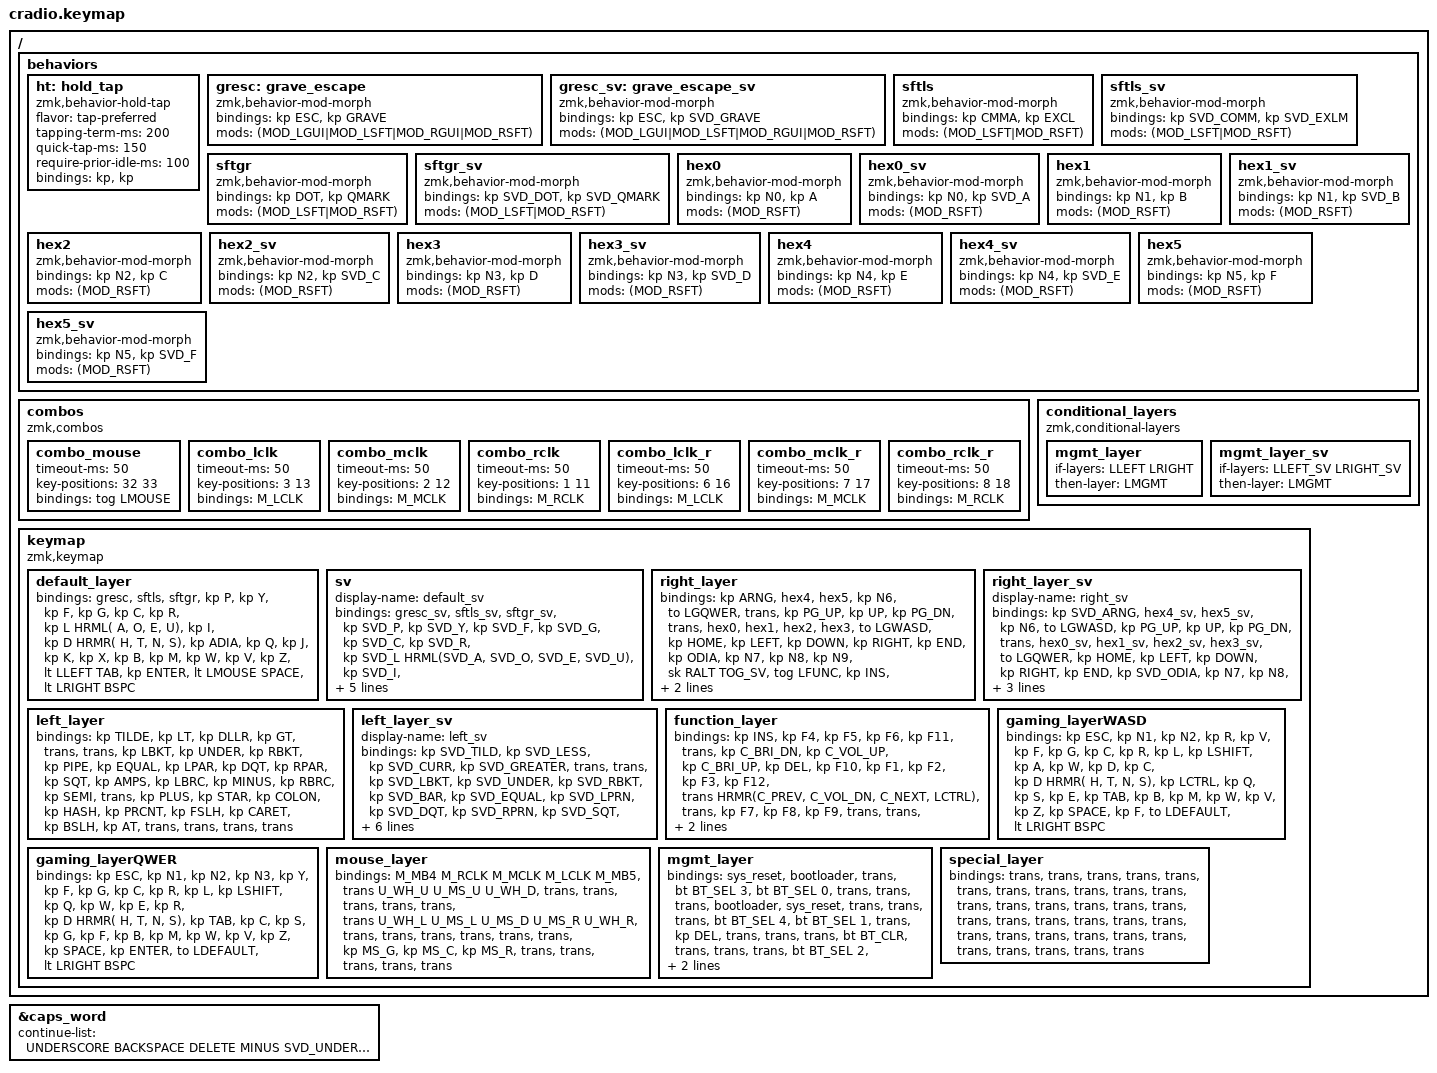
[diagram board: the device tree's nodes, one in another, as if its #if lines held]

// Copyright (c) 2022 The ZMK Contributors
// SPDX-License-Identifier: MIT

#include <behaviors.dtsi>
#include <dt-bindings/zmk/keys.h>
#include <dt-bindings/zmk/bt.h>
#include <dt-bindings/zmk/outputs.h>
#include <dt-bindings/zmk/ext_power.h>

#include "includes/se_dvorak_keys.h"

// Home row mods macro (GASC)
#define HRML(k1,k2,k3,k4)   &ht LGUI k1  &ht LALT k2   &ht LSHFT k3 &ht LCTRL k4
#define HRMR(k1,k2,k3,k4)   &ht RCTRL k1 &ht RSHFT k2  &ht LALT k3  &ht RGUI k4

// Layers suffixed with _SV are retranslated to allow dvorak input
// with language set to Dvorak, enabling non-ZMK-devices to be Dvorak
// with one global keyboard layout.
// Use KEYMAP_DRAWER define to hide *_sv layers in visual representation
#ifdef KEYMAP_DRAWER
#define LDEFAULT    0
#define LDEFAULT_SV 1
#define LRIGHT      2
#define LLEFT       3
#define LFUNC       4
#define LGQWER      5
#define LGWASD      6
#define LMOUSE      7
#define LMGMT       8

#else
#define LDEFAULT    0
#define LDEFAULT_SV 1
#define LRIGHT      2
#define LRIGHT_SV   3
#define LLEFT       4
#define LLEFT_SV    5
#define LFUNC       6
#define LGQWER      7
#define LGWASD      8
#define LMOUSE      9
#define LMGMT       10
#define LSPECIAL    11

#endif
//LGWASD + LGQWER gaming layers added 
#ifdef KEYMAP_DRAWER
    #define TOG_SV &tog LDEFAULT
#else
    #define TOG_SV &tog LDEFAULT_SV
#endif

#include "includes/mouse.dtsi"

#define ODIA RA(P)    // ö
#define ADIA RA(Q)    // ä
#define ARNG RA(W)    // å

// $mod+$modthree+key used in Sway for warpd jumps
#define MS_G LG(LS(G))
#define MS_C LG(LS(C))
#define MS_R LG(LS(R))

// Letters that gets translated to some non-alphabet key breaks caps word,
// ABCDEFGHIJKLMNOPQRsTvwXYzÅÄö
// Adding special handling for s, v, w, z and ö
// their mapping is SEMI DOT COMMA SLASH NON_US_BACKSLASH

&caps_word {
    continue-list = <UNDERSCORE BACKSPACE DELETE MINUS SVD_UNDER SVD_MINUS SEMI DOT COMMA SLASH NON_US_BACKSLASH N1 N2 N3 N4 N5 N6 N7 N8 N9 N0>;
};

/ {
    behaviors {
        ht: hold_tap {
            compatible = "zmk,behavior-hold-tap";
            #binding-cells = <2>;
            flavor = "tap-preferred";
            tapping-term-ms = <200>;
            quick-tap-ms = <150>;
            require-prior-idle-ms = <100>;
            bindings = <&kp>, <&kp>;
        };
        gresc: grave_escape {
            compatible = "zmk,behavior-mod-morph";
            #binding-cells = <0>;
            bindings = <&kp ESC>, <&kp GRAVE>;
            mods = <(MOD_LGUI|MOD_LSFT|MOD_RGUI|MOD_RSFT)>;
        };
        gresc_sv: grave_escape_sv {
            compatible = "zmk,behavior-mod-morph";
            #binding-cells = <0>;
            bindings = <&kp ESC>, <&kp SVD_GRAVE>;
            mods = <(MOD_LGUI|MOD_LSFT|MOD_RGUI|MOD_RSFT)>;
        };
        // Make LS(,) RS(,) output ! instead of <
        sftls: sftls {
            compatible = "zmk,behavior-mod-morph";
            #binding-cells = <0>;
            bindings = <&kp CMMA>, <&kp EXCL>;
            mods = <(MOD_LSFT|MOD_RSFT)>;
        };
        sftls_sv: sftls_sv {
            compatible = "zmk,behavior-mod-morph";
            #binding-cells = <0>;
            bindings = <&kp SVD_COMM>, <&kp SVD_EXLM>;
            mods = <(MOD_LSFT|MOD_RSFT)>;
        };
        // Make LS(,) RS(,) output ? instead of >
        sftgr: sftgr {
            compatible = "zmk,behavior-mod-morph";
            #binding-cells = <0>;
            bindings = <&kp DOT>, <&kp QMARK>;
            mods = <(MOD_LSFT|MOD_RSFT)>;
        };
        sftgr_sv: sftgr_sv {
            compatible = "zmk,behavior-mod-morph";
            #binding-cells = <0>;
            bindings = <&kp SVD_DOT>, <&kp SVD_QMARK>;
            mods = <(MOD_LSFT|MOD_RSFT)>;
        };

        // Make RS(0-5) output A-F
        hex0: hex0 {
            compatible = "zmk,behavior-mod-morph";
            #binding-cells = <0>;
            bindings = <&kp N0>, <&kp A>;
            mods = <(MOD_RSFT)>;
        };
        hex0_sv: hex0_sv {
            compatible = "zmk,behavior-mod-morph";
            #binding-cells = <0>;
            bindings = <&kp N0>, <&kp SVD_A>;
            mods = <(MOD_RSFT)>;
        };
        hex1: hex1 {
            compatible = "zmk,behavior-mod-morph";
            #binding-cells = <0>;
            bindings = <&kp N1>, <&kp B>;
            mods = <(MOD_RSFT)>;
        };
        hex1_sv: hex1_sv {
            compatible = "zmk,behavior-mod-morph";
            #binding-cells = <0>;
            bindings = <&kp N1>, <&kp SVD_B>;
            mods = <(MOD_RSFT)>;
        };
        hex2: hex2 {
            compatible = "zmk,behavior-mod-morph";
            #binding-cells = <0>;
            bindings = <&kp N2>, <&kp C>;
            mods = <(MOD_RSFT)>;
        };
        hex2_sv: hex2_sv {
            compatible = "zmk,behavior-mod-morph";
            #binding-cells = <0>;
            bindings = <&kp N2>, <&kp SVD_C>;
            mods = <(MOD_RSFT)>;
        };
        hex3: hex3 {
            compatible = "zmk,behavior-mod-morph";
            #binding-cells = <0>;
            bindings = <&kp N3>, <&kp D>;
            mods = <(MOD_RSFT)>;
        };
        hex3_sv: hex3_sv {
            compatible = "zmk,behavior-mod-morph";
            #binding-cells = <0>;
            bindings = <&kp N3>, <&kp SVD_D>;
            mods = <(MOD_RSFT)>;
        };
        hex4: hex4 {
            compatible = "zmk,behavior-mod-morph";
            #binding-cells = <0>;
            bindings = <&kp N4>, <&kp E>;
            mods = <(MOD_RSFT)>;
        };
        hex4_sv: hex4_sv {
            compatible = "zmk,behavior-mod-morph";
            #binding-cells = <0>;
            bindings = <&kp N4>, <&kp SVD_E>;
            mods = <(MOD_RSFT)>;
        };
        hex5: hex5 {
            compatible = "zmk,behavior-mod-morph";
            #binding-cells = <0>;
            bindings = <&kp N5>, <&kp F>;
            mods = <(MOD_RSFT)>;
        };
        hex5_sv: hex5_sv {
            compatible = "zmk,behavior-mod-morph";
            #binding-cells = <0>;
            bindings = <&kp N5>, <&kp SVD_F>;
            mods = <(MOD_RSFT)>;
        };
    };

    combos {
        compatible = "zmk,combos";
        // Pressing both thumb keys on right hand layer toggles mouse layer
        combo_mouse {
            timeout-ms = <50>;
            key-positions = <32 33>;
            bindings = <&tog LMOUSE>;
        };
        // Left hand mouse
        // Pressing both P and U gives LCLK
        combo_lclk {
            timeout-ms = <50>;
            key-positions = <3 13>;
            bindings = <M_LCLK>;
        };
        // Pressing both . and E gives MCLK
        combo_mclk {
            timeout-ms = <50>;
            key-positions = <2 12>;
            bindings = <M_MCLK>;
        };
        // Pressing both , and O gives RCLK
        combo_rclk {
            timeout-ms = <50>;
            key-positions = <1 11>;
            bindings = <M_RCLK>;
        };
        // Right hand mouse
        // Pressing both G and H gives LCLK
        combo_lclk_r {
            timeout-ms = <50>;
            key-positions = <6 16>;
            bindings = <M_LCLK>;
        };
        // Pressing both C and T gives MCLK
        combo_mclk_r {
            timeout-ms = <50>;
            key-positions = <7 17>;
            bindings = <M_MCLK>;
        };
        // Pressing both R and N gives RCLK
        combo_rclk_r {
            timeout-ms = <50>;
            key-positions = <8 18>;
            bindings = <M_RCLK>;
        };
    };

    conditional_layers {
        compatible = "zmk,conditional-layers";
        mgmt_layer {
            if-layers = <LLEFT LRIGHT>;
            then-layer = <LMGMT>;
        };
#ifndef KEYMAP_DRAWER
        mgmt_layer_sv {
            if-layers = <LLEFT_SV LRIGHT_SV>;
            then-layer = <LMGMT>;
        };
#endif
    };

    keymap {
        compatible = "zmk,keymap";
        default_layer {
            bindings = <
        //╭──────────┬──────────┬──────────┬──────────┬──────────╮   ╭──────────┬──────────┬──────────┬──────────┬──────────╮
        //│ ESC `    │  ,       │  .       │  P       │  Y       │   │  F       │  G       │  C       │  R       │  L       │
          &gresc     &sftls     &sftgr     &kp P      &kp Y          &kp F      &kp G      &kp C      &kp R      &kp L
        //├──────────┼──────────┼──────────┼──────────┼──────────┤   ├──────────┼──────────┼──────────┼──────────┼──────────┤
        //│  A       │  O       │  E       │  U       │  I       │   │  D       │  H       │  T       │  N       │  S       │
          HRML( A,      O,         E,         U)      &kp I          &kp D      HRMR( H,      T,         N,         S)
        //├──────────┼──────────┼──────────┼──────────┼──────────┤   ├──────────┼──────────┼──────────┼──────────┼──────────┤
        //│  Ä       │  Q       │  J       │  K       │  X       │   │  B       │  M       │  W       │  V       │  Z       │
          &kp ADIA   &kp Q      &kp J      &kp K      &kp X          &kp B      &kp M      &kp W      &kp V      &kp Z
        //╰──────────┴──────────┴──────────┼──────────┼──────────┤   ├──────────┼──────────┼──────────┴──────────┴──────────╯
                                        &lt LLEFT TAB &kp ENTER    &lt LMOUSE SPACE &lt LRIGHT BSPC
        //                                 ╰──────────┴──────────╯   ╰──────────┴──────────╯
            >;
        };

        sv {
            display-name = "default_sv";
            bindings = <
        //╭──────────┬──────────┬──────────┬──────────┬──────────╮   ╭──────────┬──────────┬──────────┬──────────┬──────────╮
        //│ ESC `    │  ,       │  .       │  P       │  Y       │   │  F       │  G       │  C       │  R       │  L       │
          &gresc_sv  &sftls_sv  &sftgr_sv  &kp SVD_P  &kp SVD_Y      &kp SVD_F  &kp SVD_G  &kp SVD_C  &kp SVD_R  &kp SVD_L
        //├──────────┼──────────┼──────────┼──────────┼──────────┤   ├──────────┼──────────┼──────────┼──────────┼──────────┤
        //│  A       │  O       │  E       │  U       │  I       │   │  D       │  H       │  T       │  N       │  S       │
           HRML(SVD_A, SVD_O,     SVD_E,     SVD_U)   &kp SVD_I      &kp SVD_D  HRMR(SVD_H,  SVD_T,     SVD_N,     SVD_S)
        //├──────────┼──────────┼──────────┼──────────┼──────────┤   ├──────────┼──────────┼──────────┼──────────┼──────────┤
        //│  Ä       │  Q       │  J       │  K       │  X       │   │  B       │  M       │  W       │  V       │  Z       │
         &kp SVD_ADIA &kp SVD_Q &kp SVD_J  &kp SVD_K  &kp SVD_X      &kp SVD_B  &kp SVD_M  &kp SVD_W  &kp SVD_V  &kp SVD_Z
        //╰──────────┴──────────┴──────────┼──────────┼──────────┤   ├──────────┼──────────┼──────────┴──────────┴──────────╯
#ifdef KEYMAP_DRAWER
                                     &lt LLEFT TAB &kp ENTER    &lt LMOUSE SPACE &lt LRIGHT BSPC
#else
                                     &lt LLEFT_SV TAB &kp ENTER    &lt LMOUSE SPACE &lt LRIGHT_SV BSPC
#endif
        //                                 ╰──────────┴──────────╯   ╰──────────┴──────────╯
            >;
        };

        right_layer {
            bindings = <
        //╭──────────┬──────────┬──────────┬──────────┬──────────╮   ╭──────────┬──────────┬──────────┬──────────┬──────────╮
        //│ Å        │  4  E    │  5  F    │  6       │GamingQWER│   │          │ PAGE UP  │ UP       │ PAGE_DN  │          │
          &kp ARNG   &hex4      &hex5      &kp N6     &to LGQWER     &trans     &kp PG_UP  &kp UP     &kp PG_DN  &trans
        //├──────────┼──────────┼──────────┼──────────┼──────────┤   ├──────────┼──────────┼──────────┼──────────┼──────────┤
        //│  0  A    │  1  B    │  2  C    │  3  D    │GamingWASD│   │ HOME     │ LEFT     │ DOWN     │ RIGHT    │ END      │
          &hex0      &hex1      &hex2      &hex3      &to LGWASD     &kp HOME   &kp LEFT   &kp DOWN   &kp RIGHT  &kp END
        //├──────────┼──────────┼──────────┼──────────┼──────────┤   ├──────────┼──────────┼──────────┼──────────┼──────────┤
        //│  Ö       │  7       │  8       │  9       │  Mod5    │   │          │ Toggle F │ INSERT   │ K_CMENU  │ CAPS_WORD│
          &kp ODIA   &kp N7     &kp N8     &kp N9     &sk RALT       TOG_SV     &tog LFUNC &kp INS   &kp K_CMENU &caps_word
        //╰──────────┴──────────┴──────────┼──────────┼──────────┤   ├──────────┼──────────┼──────────┴──────────┴──────────╯
                                           &trans     &kp ESC        &trans     &trans
        //                                 ╰──────────┴──────────╯   ╰──────────┴──────────╯
            >;
        };


#ifndef KEYMAP_DRAWER
        right_layer_sv {
            display-name = "right_sv";
            bindings = <
        //╭──────────┬──────────┬──────────┬──────────┬──────────╮   ╭──────────┬──────────┬──────────┬──────────┬──────────╮
        //│ Å        │  4  E    │  5  F    │  6       │          │   │          │ PAGE UP  │ UP       │ PAGE_DN  │          │
        &kp SVD_ARNG &hex4_sv   &hex5_sv   &kp N6     &to LGWASD     &kp PG_UP  &kp UP     &kp PG_DN  &trans
        //├──────────┼──────────┼──────────┼──────────┼──────────┤   ├──────────┼──────────┼──────────┼──────────┼──────────┤
        //│  0  A    │  1  B    │  2  C    │  3  D    │          │   │ HOME     │ LEFT     │ DOWN     │ RIGHT    │ END      │
          &hex0_sv   &hex1_sv   &hex2_sv   &hex3_sv   &to LGQWER     &kp HOME   &kp LEFT   &kp DOWN   &kp RIGHT  &kp END
        //├──────────┼──────────┼──────────┼──────────┼──────────┤   ├──────────┼──────────┼──────────┼──────────┼──────────┤
        //│  Ö       │  7       │  8       │  9       │  Mod5    │   │          │ Toggle F │ INSERT   │          │ CAPS_WORD│
        &kp SVD_ODIA &kp N7     &kp N8     &kp N9     &sk RALT    &tog LDEFAULT_SV &tog LFUNC &kp INS &trans     &caps_word
        //╰──────────┴──────────┴──────────┼──────────┼──────────┤   ├──────────┼──────────┼──────────┴──────────┴──────────╯
                                           &trans     &kp ESC        &trans     &trans
        //                                 ╰──────────┴──────────╯   ╰──────────┴──────────╯
            >;
        };
#endif

        left_layer {
            bindings = <
        //╭──────────┬──────────┬──────────┬──────────┬──────────╮   ╭──────────┬──────────┬──────────┬──────────┬──────────╮
        //│  ~       │  <       │  $       │  >       │          │   │          │  [       │  _       │  ]       │  |       │
          &kp TILDE  &kp LT     &kp DLLR   &kp GT     &trans         &trans     &kp LBKT   &kp UNDER  &kp RBKT   &kp PIPE
        //├──────────┼──────────┼──────────┼──────────┼──────────┤   ├──────────┼──────────┼──────────┼──────────┼──────────┤
        //│  =       │  (       │  "       │  )       │  '       │   │  &       │  {       │  -       │  }       │  ;       │
          &kp EQUAL  &kp LPAR   &kp DQT    &kp RPAR   &kp SQT        &kp AMPS   &kp LBRC   &kp MINUS  &kp RBRC   &kp SEMI 
        //├──────────┼──────────┼──────────┼──────────┼──────────┤   ├──────────┼──────────┼──────────┼──────────┼──────────┤
        //│          │  +       │  *       │  :       │  #       │   │  %       │  /       │  ^       │  \       │  @       │
          &trans     &kp PLUS   &kp STAR   &kp COLON  &kp HASH       &kp PRCNT  &kp FSLH   &kp CARET  &kp BSLH   &kp AT
        //╰──────────┴──────────┴──────────┼──────────┼──────────┤   ├──────────┼──────────┼──────────┴──────────┴──────────╯
                                           &trans     &trans         &trans     &trans
        //                                 ╰──────────┴──────────╯   ╰──────────┴──────────╯
            >;
        };

#ifndef KEYMAP_DRAWER
        left_layer_sv {
            display-name = "left_sv";
            bindings = <
        //╭──────────┬──────────┬──────────┬──────────┬──────────╮   ╭──────────┬──────────┬──────────┬──────────┬──────────╮
        //│  ~       │  <       │  $       │  >       │          │   │          │  [       │  _       │  ]       │  |       │
      &kp SVD_TILD &kp SVD_LESS &kp SVD_CURR &kp SVD_GREATER &trans &trans &kp SVD_LBKT &kp SVD_UNDER &kp SVD_RBKT &kp SVD_BAR
        //├──────────┼──────────┼──────────┼──────────┼──────────┤   ├──────────┼──────────┼──────────┼──────────┼──────────┤
        //│  =       │  (       │  "       │  )       │  '       │   │  &       │  {       │  -       │  }       │  ;       │
      &kp SVD_EQUAL &kp SVD_LPRN &kp SVD_DQT  &kp SVD_RPRN &kp SVD_SQT &kp SVD_AMPR &kp SVD_LBRC &kp SVD_MINUS &kp SVD_RBRC &kp SVD_SEMI 
        //├──────────┼──────────┼──────────┼──────────┼──────────┤   ├──────────┼──────────┼──────────┼──────────┼──────────┤
        //│          │  +       │  *       │  :       │  #       │   │  %       │  /       │  ^       │  \       │  @       │
          &trans  &kp SVD_PLUS &kp SVD_ASTR &kp SVD_COLON &kp SVD_HASH &kp SVD_PERC &kp SVD_FSLH &kp SVD_CIRC &kp SVD_BSLH &kp SVD_AT
        //╰──────────┴──────────┴──────────┼──────────┼──────────┤   ├──────────┼──────────┼──────────┴──────────┴──────────╯
                                           &trans     &trans         &trans     &trans
        //                                 ╰──────────┴──────────╯   ╰──────────┴──────────╯
            >;
        };
#endif

        function_layer {
            bindings = <
        //╭──────────┬──────────┬──────────┬──────────┬──────────╮   ╭───────────┬──────────┬──────────┬──────────┬──────────╮
        //│ INSERT   │   F4     │   F5     │   F6     │   F11    │   │           │ BL-      │ Vol Up   │ BL+      │ DEL      │
          &kp INS    &kp F4     &kp F5     &kp F6     &kp F11        &trans   &kp C_BRI_DN &kp C_VOL_UP &kp C_BRI_UP &kp DEL
        //├──────────┼──────────┼──────────┼──────────┼──────────┤   ├───────────┼──────────┼──────────┼──────────┼──────────┤
        //│   F10    │   F1     │   F2     │   F3     │   F12    │   │           │  C_Prev  │ Vol Down │ C_Next   │  CTRL    │
          &kp F10    &kp F1     &kp F2     &kp F3     &kp F12        &trans      HRMR(C_PREV, C_VOL_DN,  C_NEXT,    LCTRL)
        //├──────────┼──────────┼──────────┼──────────┼──────────┤   ├───────────┼──────────┼──────────┼──────────┼──────────┤
        //│          │   F7     │   F8     │   F9     │          │   │           │ Toggle F │Play/Pause│  Mute    │  Alt     │
          &trans     &kp F7     &kp F8     &kp F9     &trans         &trans     &tog LFUNC &kp C_PP   &kp C_MUTE &kp LALT
        //╰──────────┴──────────┴──────────┼──────────┼──────────┤   ├───────────┼──────────┼──────────┴──────────┴──────────╯
                                           &trans     &trans         &trans      &trans
        //                                 ╰──────────┴──────────╯   ╰───────────┴──────────╯
            >;
        };
        gaming_layerWASD {
            bindings = <
        //╭──────────┬──────────┬──────────┬──────────┬──────────╮   ╭──────────┬──────────┬──────────┬──────────┬──────────╮
        //│   ESC    │   1      │   2      │   R      │   V      │   │   F      │   G      │   C      │   R      │   L      │
          &kp ESC    &kp N1     &kp N2     &kp R      &kp V          &kp F      &kp G      &kp C      &kp R      &kp L
        //├──────────┼──────────┼──────────┼──────────┼──────────┤   ├──────────┼──────────┼──────────┼──────────┼──────────┤
        //│   LSHIFT │   A      │   W      │   D      │   C      │   │   D      │     H    │   T      │   N      │   S      │
          &kp LSHIFT &kp A      &kp W      &kp D      &kp C          &kp D      HRMR( H,       T,         N,         S)
        //├──────────┼──────────┼──────────┼──────────┼──────────┤   ├──────────┼──────────┼──────────┼──────────┼──────────┤
        //│   LCtrl  │   Q      │   S      │   E      │   Tab    │   │   B      │   M      │   W      │   V      │   Z      │
          &kp LCTRL  &kp Q      &kp S      &kp E      &kp TAB        &kp B      &kp M      &kp W      &kp V      &kp Z
        //╰──────────┴──────────┴──────────┼──────────┼──────────┤   ├──────────┼──────────┼──────────┴──────────┴──────────╯
                                           &kp SPACE  &kp F          &to LDEFAULT &lt LRIGHT BSPC
        //                                 ╰──────────┴──────────╯   ╰──────────┴──────────╯
            >;
        };
        gaming_layerQWER {
            bindings = <
        //╭──────────┬──────────┬──────────┬──────────┬──────────╮   ╭──────────┬──────────┬──────────┬──────────┬──────────╮
        //│   ESC    │   1      │   2      │   3      │   Y      │   │   F      │   G      │   C      │   R      │   L      │
          &kp ESC    &kp N1     &kp N2     &kp N3     &kp Y          &kp F      &kp G      &kp C      &kp R      &kp L
        //├──────────┼──────────┼──────────┼──────────┼──────────┤   ├──────────┼──────────┼──────────┼──────────┼──────────┤
        //    LShift │   Q      │   W      │   E      │   R      │   │   D      │     H    │   T      │   N      │   S      │
          &kp LSHIFT &kp Q      &kp W      &kp E      &kp R          &kp D      HRMR( H,       T,         N,         S)
        //├──────────┼──────────┼──────────┼──────────┼──────────┤   ├──────────┼──────────┼──────────┼──────────┼──────────┤
        //│   TAB    │   C      │   S      │   G      │   F      │   │   B      │   M      │   W      │   V      │   Z      │
          &kp TAB    &kp C      &kp S      &kp G      &kp F          &kp B      &kp M      &kp W      &kp V      &kp Z
        //╰──────────┴──────────┴──────────┼──────────┼──────────┤   ├──────────┼──────────┼──────────┴──────────┴──────────╯
                                           &kp SPACE  &kp ENTER      &to LDEFAULT &lt LRIGHT BSPC
        //                                 ╰──────────┴──────────╯   ╰──────────┴──────────╯
            >;
        };
        mouse_layer {
            bindings = <
        //╭──────────┬──────────┬──────────┬──────────┬──────────╮   ╭──────────┬──────────┬──────────┬──────────┬──────────╮
        //│          │          │          │          │          │   │          │ SCRL_UP  │ MMV_UP   │ SCRL_DN  │          │
          M_MB4      M_RCLK     M_MCLK     M_LCLK     M_MB5          &trans     U_WH_U     U_MS_U     U_WH_D     &trans
        //├──────────┼──────────┼──────────┼──────────┼──────────┤   ├──────────┼──────────┼──────────┼──────────┼──────────┤
        //│          │          │          │          │          │   │ SCRL_LEFT│ MMV_LEFT │ MMV_DOWN │ MMV_RIGHT│SCRL_RIGHT│
          &trans     &trans     &trans     &trans     &trans         U_WH_L     U_MS_L     U_MS_D     U_MS_R     U_WH_R
        //├──────────┼──────────┼──────────┼──────────┼──────────┤   ├──────────┼──────────┼──────────┼──────────┼──────────┤
        //│          │          │          │          │          │   │          │          │          │          │          │
          &trans     &trans     &trans     &trans     &trans         &trans     &kp MS_G   &kp MS_C   &kp MS_R   &trans
        //╰──────────┴──────────┴──────────┼──────────┼──────────┤   ├──────────┼──────────┼──────────┴──────────┴─────────
                                           &trans     &trans         &trans     &trans
        //                                 ╰──────────┴──────────╯   ╰──────────┴──────────╯
            >;
        };
        mgmt_layer {
            bindings = <
        //╭──────────┬──────────┬──────────┬──────────┬──────────╮   ╭──────────┬──────────┬──────────┬──────────┬──────────╮
        //│ RESET    │BOOTLOADER│          │PROFILE 3 │PROFILE 0 │   │          │          │          │BOOTLOADER│ RESET    │
          &sys_reset &bootloader &trans &bt BT_SEL 3  &bt BT_SEL 0   &trans     &trans     &trans    &bootloader &sys_reset
        //├──────────┼──────────┼──────────┼──────────┼──────────┤   ├──────────┼──────────┼──────────┼──────────┼──────────┤
        //│          │          │          │PROFILE 4 │PROFILE 1 │   │          │ DELETE   │          │          │          │
          &trans     &trans     &trans &bt BT_SEL 4   &bt BT_SEL 1   &trans     &kp DEL    &trans     &trans     &trans
        //├──────────┼──────────┼──────────┼──────────┼──────────┤   ├──────────┼──────────┼──────────┼──────────┼──────────┤
        //│ CLEAR BT │          │          │          │PROFILE 2 │   │ BT/USB   │ EXT_PWR  │          │          │          │
          &bt BT_CLR &trans     &trans     &trans     &bt BT_SEL 2  &out OUT_TOG &ext_power EP_TOG    &trans &trans &trans
        //╰──────────┴──────────┴──────────┼──────────┼──────────┤   ├──────────┼──────────┼──────────┴──────────┴──────────╯
                                           &trans     &trans         &trans     &trans
        //                                 ╰──────────┴──────────╯   ╰──────────┴──────────╯
            >;
        };

#ifdef THIS_IS_INFO_ONLY
        special_layer {
            bindings = <
        //╭──────────┬──────────┬──────────┬──────────┬──────────╮   ╭──────────┬──────────┬──────────┬──────────┬──────────╮
        //│ ´ (Dead) │ ç        │ ˙ (Dead) │ ö        │ ü        │   │          │          │ ©        │ ®        │ ø        │
          &trans     &trans     &trans     &trans     &trans         &trans     &trans     &trans     &trans     &trans
        //├──────────┼──────────┼──────────┼──────────┼──────────┤   ├──────────┼──────────┼──────────┼──────────┼──────────┤
        //│ á        │ ó        │ é        │ ú        │ í        │   │ ð        │          │ þ        │ ñ        │ ß        │
          &trans     &trans     &trans     &trans     &trans         &trans     &trans     &trans     &trans     &trans
        //├──────────┼──────────┼──────────┼──────────┼──────────┤   ├──────────┼──────────┼──────────┼──────────┼──────────┤
        //│ ` (Dead) │ ä        │          │ œ        │          │   │          │ µ        │ å        │          │ æ        │
          &trans     &trans     &trans     &trans     &trans         &trans     &trans     &trans     &trans     &trans
        //╰──────────┴──────────┴──────────┼──────────┼──────────┤   ├──────────┼──────────┼──────────┴──────────┴──────────╯
                                           &trans     &trans         &trans     &trans
        //                                 ╰──────────┴──────────╯   ╰──────────┴──────────╯
            >;
        };
#endif
    };
};
